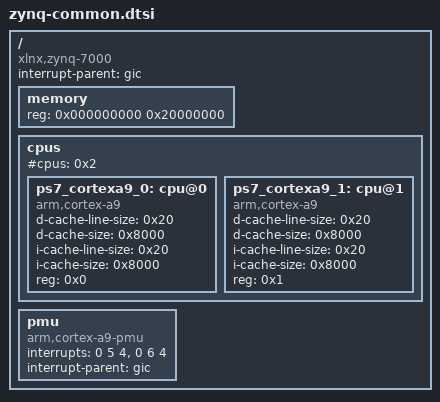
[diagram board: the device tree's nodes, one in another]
/ {
	compatible = "xlnx,zynq-7000";
	#address-cells = <1>;
	#size-cells = <1>;
	interrupt-parent = <&gic>;

	memory {
                device_type = "memory";
                reg = <0x000000000 0x20000000>;
        };

	cpus {
		#address-cells = <1>;
		#cpus = <0x2>;
		#size-cells = <0>;
		ps7_cortexa9_0: cpu@0 {
			compatible = "arm,cortex-a9";
			d-cache-line-size = <0x20>;
			d-cache-size = <0x8000>;
			device_type = "cpu";
			i-cache-line-size = <0x20>;
			i-cache-size = <0x8000>;
			reg = <0x0>;
		};
		ps7_cortexa9_1: cpu@1 {
			compatible = "arm,cortex-a9";
			d-cache-line-size = <0x20>;
			d-cache-size = <0x8000>;
			device_type = "cpu";
			i-cache-line-size = <0x20>;
			i-cache-size = <0x8000>;
			reg = <0x1>;
		};
	};

	pmu {
		compatible = "arm,cortex-a9-pmu";
		interrupts = <0 5 4>, <0 6 4>;
		interrupt-parent = <&gic>;
	};
};
